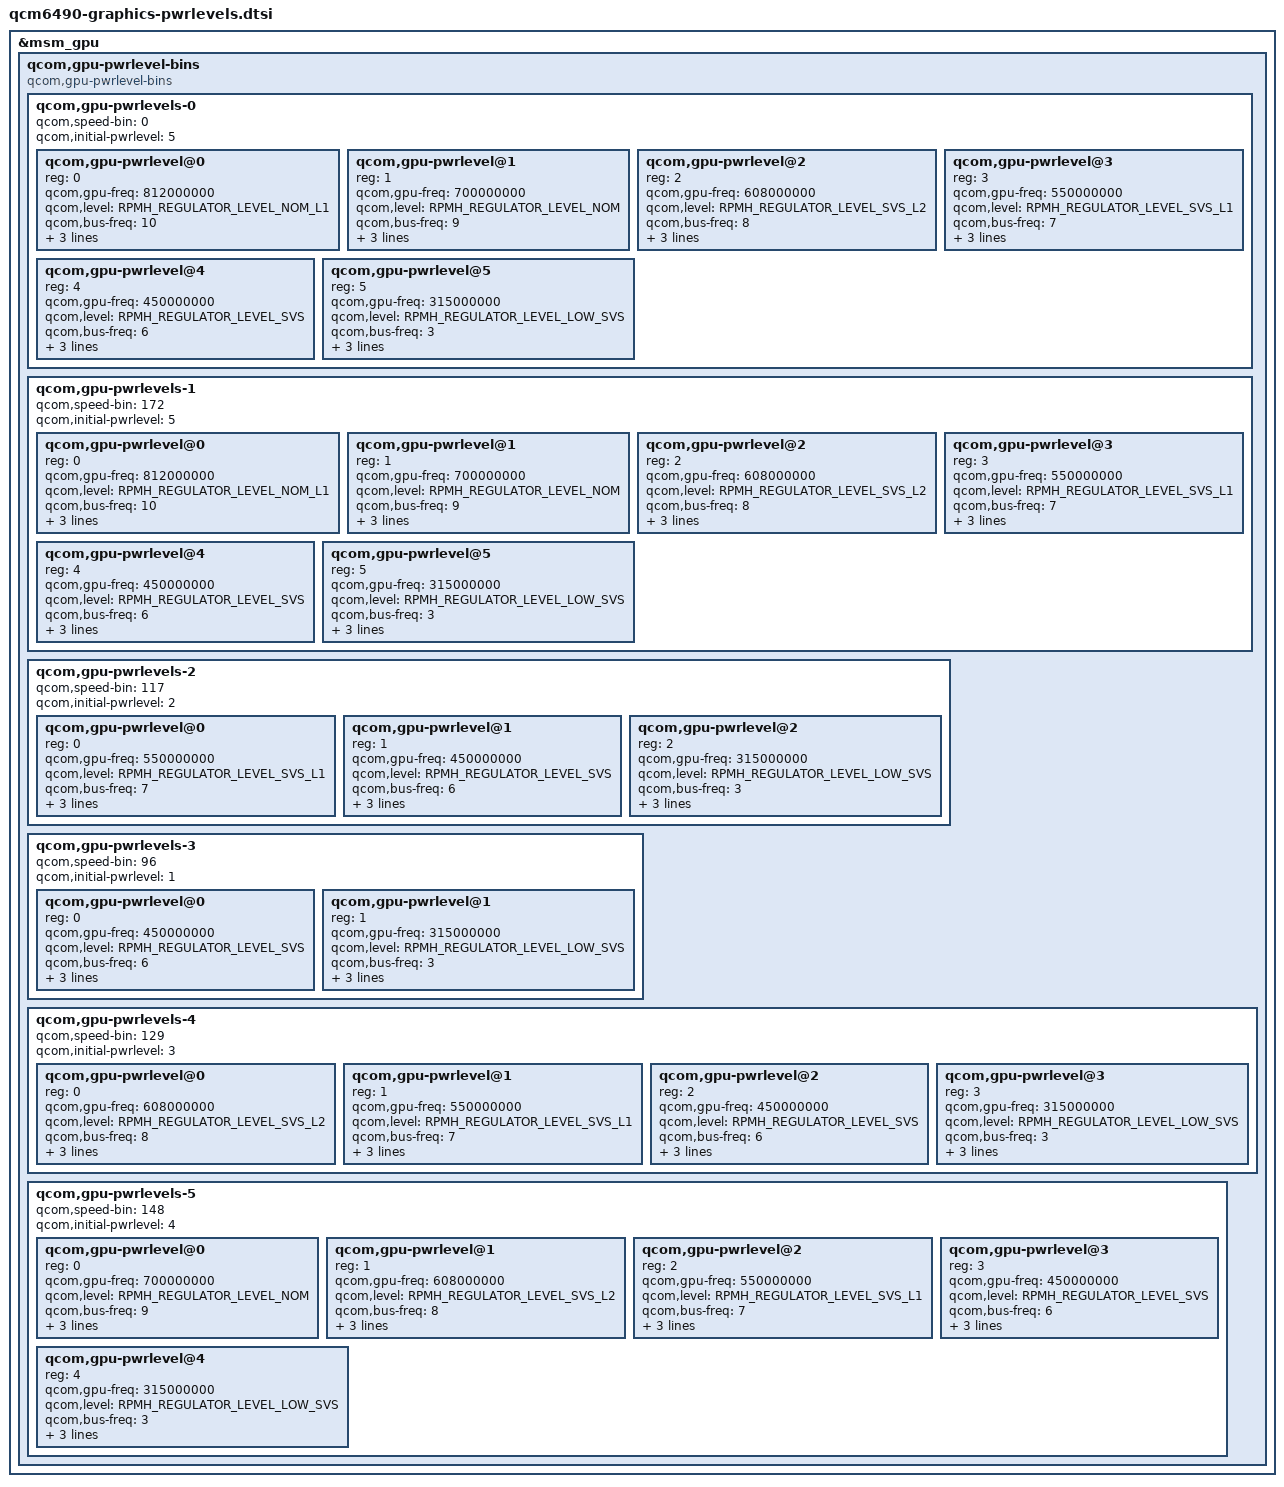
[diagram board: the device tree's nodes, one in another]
/*
 * Copyright (c) 2024 Qualcomm Innovation Center, Inc. All rights reserved.
 */
// SPDX-License-Identifier: BSD-3-Clause

&msm_gpu {
	/*
	 * Speed-bin zero is default speed bin.
	 * For rest of the speed bins, speed-bin value
	 * is calculated as FMAX/4.8 MHz round up to zero
	 * decimal places plus two margin to account for
	 * clock jitters.
	 */
	qcom,gpu-pwrlevel-bins {
		#address-cells = <1>;
		#size-cells = <0>;

		compatible = "qcom,gpu-pwrlevel-bins";
		qcom,gpu-pwrlevels-0 {
			#address-cells = <1>;
			#size-cells = <0>;

			qcom,speed-bin = <0>;
			qcom,initial-pwrlevel = <5>;

			qcom,gpu-pwrlevel@0 {
				reg = <0>;
				qcom,gpu-freq = <812000000>;
				qcom,level = <RPMH_REGULATOR_LEVEL_NOM_L1>;

				qcom,bus-freq = <10>;
				qcom,bus-min = <9>;
				qcom,bus-max = <10>;

				qcom,acd-level = <0x802B5FFD>;
			};

			qcom,gpu-pwrlevel@1 {
				reg = <1>;
				qcom,gpu-freq = <700000000>;
				qcom,level = <RPMH_REGULATOR_LEVEL_NOM>;

				qcom,bus-freq = <9>;
				qcom,bus-min = <8>;
				qcom,bus-max = <10>;

				qcom,acd-level = <0x802B5FFD>;
			};

			qcom,gpu-pwrlevel@2 {
				reg = <2>;
				qcom,gpu-freq = <608000000>;
				qcom,level = <RPMH_REGULATOR_LEVEL_SVS_L2>;

				qcom,bus-freq = <8>;
				qcom,bus-min = <7>;
				qcom,bus-max = <10>;

				qcom,acd-level = <0x802B5FFD>;
			};

			qcom,gpu-pwrlevel@3 {
				reg = <3>;
				qcom,gpu-freq = <550000000>;
				qcom,level = <RPMH_REGULATOR_LEVEL_SVS_L1>;

				qcom,bus-freq = <7>;
				qcom,bus-min = <6>;
				qcom,bus-max = <9>;

				qcom,acd-level = <0x802B5FFD>;
			};

			qcom,gpu-pwrlevel@4 {
				reg = <4>;
				qcom,gpu-freq = <450000000>;
				qcom,level = <RPMH_REGULATOR_LEVEL_SVS>;

				qcom,bus-freq = <6>;
				qcom,bus-min = <6>;
				qcom,bus-max = <8>;

				qcom,acd-level = <0x802B5FFD>;
			};

			qcom,gpu-pwrlevel@5 {
				reg = <5>;
				qcom,gpu-freq = <315000000>;
				qcom,level = <RPMH_REGULATOR_LEVEL_LOW_SVS>;

				qcom,bus-freq = <3>;
				qcom,bus-min = <2>;
				qcom,bus-max = <7>;

				qcom,acd-level = <0x882F5FFD>;
			};
		};

		qcom,gpu-pwrlevels-1 {
			#address-cells = <1>;
			#size-cells = <0>;

			/* Keeping speed bin for FMAX 812 */
			qcom,speed-bin = <172>;
			qcom,initial-pwrlevel = <5>;

			qcom,gpu-pwrlevel@0 {
				reg = <0>;
				qcom,gpu-freq = <812000000>;
				qcom,level = <RPMH_REGULATOR_LEVEL_NOM_L1>;

				qcom,bus-freq = <10>;
				qcom,bus-min = <9>;
				qcom,bus-max = <10>;

				qcom,acd-level = <0x802B5FFD>;
			};

			qcom,gpu-pwrlevel@1 {
				reg = <1>;
				qcom,gpu-freq = <700000000>;
				qcom,level = <RPMH_REGULATOR_LEVEL_NOM>;

				qcom,bus-freq = <9>;
				qcom,bus-min = <8>;
				qcom,bus-max = <10>;

				qcom,acd-level = <0x802B5FFD>;
			};

			qcom,gpu-pwrlevel@2 {
				reg = <2>;
				qcom,gpu-freq = <608000000>;
				qcom,level = <RPMH_REGULATOR_LEVEL_SVS_L2>;

				qcom,bus-freq = <8>;
				qcom,bus-min = <7>;
				qcom,bus-max = <10>;

				qcom,acd-level = <0x802B5FFD>;
			};

			qcom,gpu-pwrlevel@3 {
				reg = <3>;
				qcom,gpu-freq = <550000000>;
				qcom,level = <RPMH_REGULATOR_LEVEL_SVS_L1>;

				qcom,bus-freq = <7>;
				qcom,bus-min = <6>;
				qcom,bus-max = <9>;

				qcom,acd-level = <0x802B5FFD>;
			};

			qcom,gpu-pwrlevel@4 {
				reg = <4>;
				qcom,gpu-freq = <450000000>;
				qcom,level = <RPMH_REGULATOR_LEVEL_SVS>;

				qcom,bus-freq = <6>;
				qcom,bus-min = <6>;
				qcom,bus-max = <8>;

				qcom,acd-level = <0x802B5FFD>;
			};

			qcom,gpu-pwrlevel@5 {
				reg = <5>;
				qcom,gpu-freq = <315000000>;
				qcom,level = <RPMH_REGULATOR_LEVEL_LOW_SVS>;

				qcom,bus-freq = <3>;
				qcom,bus-min = <2>;
				qcom,bus-max = <7>;

				qcom,acd-level = <0x882F5FFD>;
			};
		};

		qcom,gpu-pwrlevels-2 {
			#address-cells = <1>;
			#size-cells = <0>;

			qcom,speed-bin = <117>;
			qcom,initial-pwrlevel = <2>;

			qcom,gpu-pwrlevel@0 {
				reg = <0>;
				qcom,gpu-freq = <550000000>;
				qcom,level = <RPMH_REGULATOR_LEVEL_SVS_L1>;

				qcom,bus-freq = <7>;
				qcom,bus-min = <6>;
				qcom,bus-max = <9>;

				qcom,acd-level = <0x802B5FFD>;
			};

			qcom,gpu-pwrlevel@1 {
				reg = <1>;
				qcom,gpu-freq = <450000000>;
				qcom,level = <RPMH_REGULATOR_LEVEL_SVS>;

				qcom,bus-freq = <6>;
				qcom,bus-min = <6>;
				qcom,bus-max = <8>;

				qcom,acd-level = <0x802B5FFD>;
			};

			qcom,gpu-pwrlevel@2 {
				reg = <2>;
				qcom,gpu-freq = <315000000>;
				qcom,level = <RPMH_REGULATOR_LEVEL_LOW_SVS>;

				qcom,bus-freq = <3>;
				qcom,bus-min = <2>;
				qcom,bus-max = <7>;

				qcom,acd-level = <0x882F5FFD>;
			};
		};
		qcom,gpu-pwrlevels-3 {
			#address-cells = <1>;
			#size-cells = <0>;

			qcom,speed-bin = <96>;
			qcom,initial-pwrlevel = <1>;

			qcom,gpu-pwrlevel@0 {
				reg = <0>;
				qcom,gpu-freq = <450000000>;
				qcom,level = <RPMH_REGULATOR_LEVEL_SVS>;

				qcom,bus-freq = <6>;
				qcom,bus-min = <6>;
				qcom,bus-max = <8>;

				qcom,acd-level = <0x802B5FFD>;
			};

			qcom,gpu-pwrlevel@1 {
				reg = <1>;
				qcom,gpu-freq = <315000000>;
				qcom,level = <RPMH_REGULATOR_LEVEL_LOW_SVS>;

				qcom,bus-freq = <3>;
				qcom,bus-min = <2>;
				qcom,bus-max = <7>;

				qcom,acd-level = <0x882F5FFD>;
			};
		};

		qcom,gpu-pwrlevels-4 {
			#address-cells = <1>;
			#size-cells = <0>;

			qcom,speed-bin = <129>;
			qcom,initial-pwrlevel = <3>;

			qcom,gpu-pwrlevel@0 {
				reg = <0>;
				qcom,gpu-freq = <608000000>;
				qcom,level = <RPMH_REGULATOR_LEVEL_SVS_L2>;

				qcom,bus-freq = <8>;
				qcom,bus-min = <7>;
				qcom,bus-max = <10>;

				qcom,acd-level = <0x802B5FFD>;
			};

			qcom,gpu-pwrlevel@1 {
				reg = <1>;
				qcom,gpu-freq = <550000000>;
				qcom,level = <RPMH_REGULATOR_LEVEL_SVS_L1>;

				qcom,bus-freq = <7>;
				qcom,bus-min = <6>;
				qcom,bus-max = <9>;

				qcom,acd-level = <0x802B5FFD>;
			};

			qcom,gpu-pwrlevel@2 {
				reg = <2>;
				qcom,gpu-freq = <450000000>;
				qcom,level = <RPMH_REGULATOR_LEVEL_SVS>;

				qcom,bus-freq = <6>;
				qcom,bus-min = <6>;
				qcom,bus-max = <8>;

				qcom,acd-level = <0x802B5FFD>;
			};

			qcom,gpu-pwrlevel@3 {
				reg = <3>;
				qcom,gpu-freq = <315000000>;
				qcom,level = <RPMH_REGULATOR_LEVEL_LOW_SVS>;

				qcom,bus-freq = <3>;
				qcom,bus-min = <2>;
				qcom,bus-max = <7>;

				qcom,acd-level = <0x882F5FFD>;
			};
		};

		qcom,gpu-pwrlevels-5 {
			#address-cells = <1>;
			#size-cells = <0>;

			qcom,speed-bin = <148>;
			qcom,initial-pwrlevel = <4>;

			qcom,gpu-pwrlevel@0 {
				reg = <0>;
				qcom,gpu-freq = <700000000>;
				qcom,level = <RPMH_REGULATOR_LEVEL_NOM>;

				qcom,bus-freq = <9>;
				qcom,bus-min = <8>;
				qcom,bus-max = <10>;

				qcom,acd-level = <0x802B5FFD>;
			};

			qcom,gpu-pwrlevel@1 {
				reg = <1>;
				qcom,gpu-freq = <608000000>;
				qcom,level = <RPMH_REGULATOR_LEVEL_SVS_L2>;

				qcom,bus-freq = <8>;
				qcom,bus-min = <7>;
				qcom,bus-max = <10>;

				qcom,acd-level = <0x802B5FFD>;
			};

			qcom,gpu-pwrlevel@2 {
				reg = <2>;
				qcom,gpu-freq = <550000000>;
				qcom,level = <RPMH_REGULATOR_LEVEL_SVS_L1>;

				qcom,bus-freq = <7>;
				qcom,bus-min = <6>;
				qcom,bus-max = <9>;

				qcom,acd-level = <0x802B5FFD>;
			};

			qcom,gpu-pwrlevel@3 {
				reg = <3>;
				qcom,gpu-freq = <450000000>;
				qcom,level = <RPMH_REGULATOR_LEVEL_SVS>;

				qcom,bus-freq = <6>;
				qcom,bus-min = <6>;
				qcom,bus-max = <8>;

				qcom,acd-level = <0x802B5FFD>;
			};

			qcom,gpu-pwrlevel@4 {
				reg = <4>;
				qcom,gpu-freq = <315000000>;
				qcom,level = <RPMH_REGULATOR_LEVEL_LOW_SVS>;

				qcom,bus-freq = <3>;
				qcom,bus-min = <2>;
				qcom,bus-max = <7>;

				qcom,acd-level = <0x882F5FFD>;
			};
		};
	};
};
